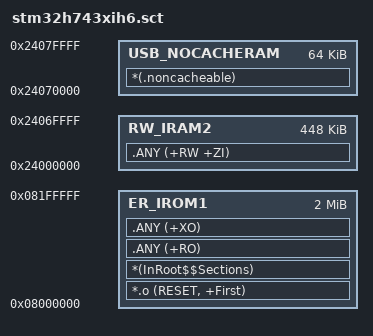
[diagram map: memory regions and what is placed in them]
; *************************************************************
; *** Scatter-Loading Description File generated by uVision ***
; *************************************************************

LR_IROM1 0x08000000 0x00200000  {    ; load region size_region
  ER_IROM1 0x08000000 0x00200000  {  ; load address = execution address
   *.o (RESET, +First)
   *(InRoot$$Sections)
   .ANY (+RO)
   .ANY (+XO)
  }
  RW_IRAM2 0x24000000 0x00070000  {  ; RW data
   .ANY (+RW +ZI)
  }
  USB_NOCACHERAM 0x24070000 0x00010000  {  ; RW data
   *(.noncacheable)
  }
}

